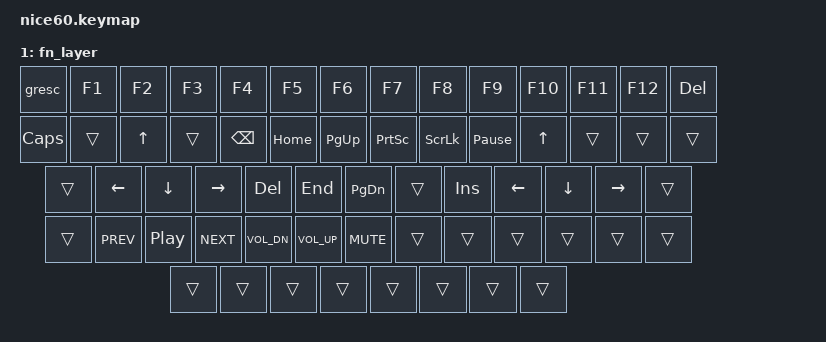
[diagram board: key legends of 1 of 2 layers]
/*
 * Copyright (c) 2021 Nick Winans
 *
 * SPDX-License-Identifier: MIT
 */

#include <behaviors.dtsi>
#include <dt-bindings/zmk/keys.h>
#include <dt-bindings/zmk/rgb.h>
#include <dt-bindings/zmk/bt.h>
#include <dt-bindings/zmk/outputs.h>
#include <dt-bindings/zmk/reset.h>
#include <dt-bindings/zmk/ext_power.h>

/ {
	keymap {
		compatible = "zmk,keymap";
		
		default_layer {
// ----------------------------------------------------------------------------------------------------------------------
// |   `   |   1   |   2   |   3   |   4   |   5   |   6   |   7   |   8   |   9   |   0   |   -   |   =   |    BKSP    |
// |  TAB   |   Q   |   W   |   E   |   R   |   T   |   Y   |   U   |   I   |   O   |   P   |   [   |   ]   |    "|"    |
// |  MO(1)  |   A   |   S   |   D   |   F   |   G   |   H   |   J   |   K   |   L   |   ;   |   '   |       ENTER      |
// |  SHIFT   |   Z   |   X   |   C   |   V   |   B   |   N   |   M   |   ,   |   .   |   /   |          SHIFT          |
// |   CTL   |   WIN   |   ALT   |                   SPACE                      |   ALT   |   WIN   |   MO(1) |   CTL   |
// ----------------------------------------------------------------------------------------------------------------------
			bindings = <
	&kp GRAVE	&kp N1	&kp N2	&kp N3	&kp N4	&kp N5	&kp N6	&kp N7	&kp N8	&kp N9	&kp N0	&kp MINUS	&kp EQUAL	&kp BSPC
	&kp TAB	&kp Q	&kp W	&kp E	&kp R	&kp T	&kp Y	&kp U	&kp I	&kp O	&kp P	&kp LBKT	&kp RBKT	&kp BSLH
    &mo 1	&kp A	&kp S	&kp D	&kp F	&kp G	&kp H	&kp J	&kp K	&kp L	&kp SEMI	&kp SQT	&kp RET
	&kp LSHFT	&kp Z	&kp X	&kp C	&kp V	&kp B	&kp N	&kp M	&kp COMMA	&kp DOT	&kp FSLH	&kp RSHFT
	&kp LCTRL	&kp LGUI	&kp LALT	&kp SPACE	&kp RALT	&kp RGUI	&mo 1 	&kp RCTRL
			>;
		};

		fn_layer {
// ---------------------------------------------------------------------------------------------------------------------
// |  ESC  |   F1  |   F2  |  F3   |  F4   |  F5   |  F6   |  F7   |  F8   |  F9   |  F10  |  F11  |  F12  |    DEL    |
// |  CAPS  |       |   UP  |       |  BKSP |  HOME |  PGUP |  PRN  |  SLCK |  PAUS |  UP   |       |       |          |
// |         |  LT   |  DN   |  RT   |  DEL  |  END  |  PGDN |       |  INS  |  LT   |  DN   |  RT   |                 |
// |          |  PREV |  PLAY |  NEXT |  VOL- |  VOL+ |  MUTE |       |       |       |       |                        |
// |         |         |         |                                             |         |         |         |         |
// ---------------------------------------------------------------------------------------------------------------------
			bindings = <
	&gresc			&kp F1		&kp F2		&kp F3		&kp F4		&kp F5		&kp F6		&kp F7		&kp F8		&kp F9		&kp F10		&kp F11		&kp F12		 		 &kp DEL 
	&kp CAPS	  	 &trans		 &kp UP		 &trans		 &kp BSPC	 &kp HOME    &kp PG_UP	 &kp PSCRN	 &kp SLCK	 &kp PAUSE_BREAK &kp UP	 &trans		 &trans          	  &trans 
	&trans  		  &kp LEFT    &kp DOWN	  &kp RIGHT	  &kp DEL 	  &kp END	  &kp PG_DN   &trans 	  &kp INS     &kp LEFT    &kp DOWN	  &kp RIGHT		        		  &trans
	&trans    		   &kp C_PREV  &kp C_PP	   &kp C_NEXT  &kp C_VOL_DN &kp C_VOL_UP &kp C_MUTE &trans	   &trans	   &trans	   &trans	   &trans                  		  &trans
	&trans			&trans   		&trans							&trans                          &trans      	&trans      	&trans 								      &trans
			>;
		};
	};
};
